# STM32F205 register map
File version: 1.2
CPU: CM3 r1p1, little endian, no MPU, no FPU, 4 interrupt priority bits
Registers are 32-bit, read-write, reset 0x0 unless marked. A register's access mark holds for its fields unless they carry their own. Offsets are from the block's base; [hi:lo] are bit positions; {n}, {i} and the like mark numbered series.

## OTG_FS_PWRCLK — USB on the go full speed
Base 0x50000E00
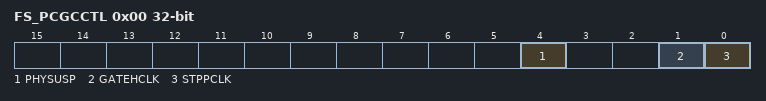
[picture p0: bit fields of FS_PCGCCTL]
0x00 FS_PCGCCTL — OTG_FS power and clock gating control register (OTG_FS_PCGCCTL)
  [4] PHYSUSP — PHY Suspended
  [1] GATEHCLK
  [0] STPPCLK — Stop PHY clock

## OTG_HS_PWRCLK — USB on the go high speed
Base 0x40040E00
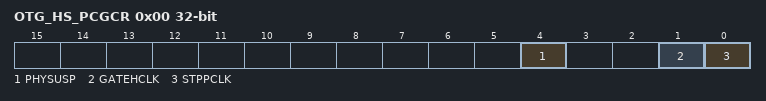
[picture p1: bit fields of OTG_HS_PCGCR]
0x00 OTG_HS_PCGCR — Power and clock gating control register
  [4] PHYSUSP — PHY suspended
  [1] GATEHCLK
  [0] STPPCLK — Stop PHY clock

## PWR — Power control
Base 0x40007000
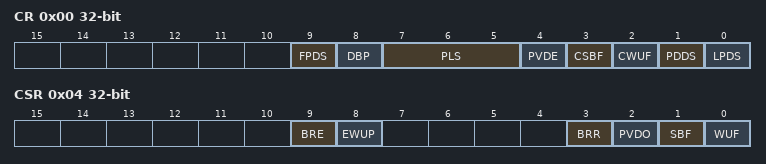
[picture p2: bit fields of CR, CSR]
0x00 CR — power control register
  [9] FPDS — Flash power down in Stop mode
  [8] DBP — Disable backup domain write protection
  [7:5] PLS — PVD level selection
  [4] PVDE — Power voltage detector enable
  [3] CSBF — Clear standby flag
  [2] CWUF — Clear wakeup flag
  [1] PDDS — Power down deepsleep
  [0] LPDS — Low-power deep sleep
0x04 CSR access per field — power control/status register
  [9] BRE rw — Backup regulator enable
  [8] EWUP rw — Enable WKUP pin
  [3] BRR ro — Backup regulator ready
  [2] PVDO ro — PVD output
  [1] SBF ro — Standby flag
  [0] WUF ro — Wakeup flag

## RNG — Random number generator
Base 0x50060800
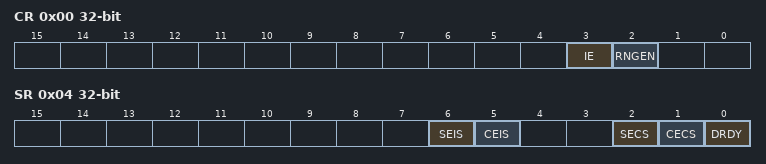
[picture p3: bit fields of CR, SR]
0x00 CR — control register
  [3] IE — Interrupt enable
  [2] RNGEN — Random number generator enable
0x04 SR access per field — status register
  [6] SEIS rw — Seed error interrupt status
  [5] CEIS rw — Clock error interrupt status
  [2] SECS ro — Seed error current status
  [1] CECS ro — Clock error current status
  [0] DRDY ro — Data ready
0x08 DR ro — data register
  [31:0] RNDATA — Random data

## SPI1 — Serial peripheral interface
Base 0x40013000
Same registers: SPI2 0x40003800, SPI3 0x40003C00
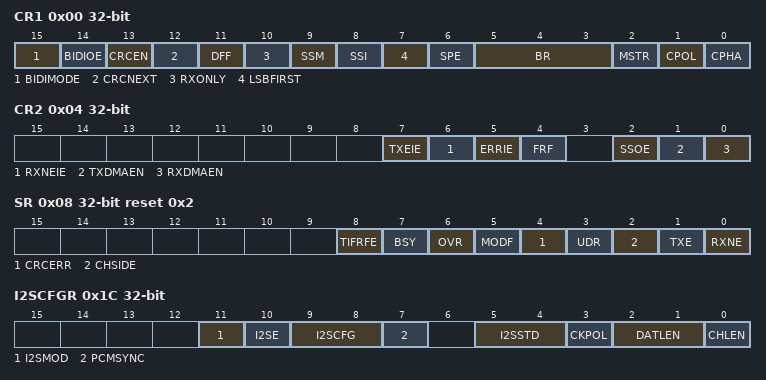
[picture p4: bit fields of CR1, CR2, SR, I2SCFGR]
0x00 CR1 — control register 1
  [15] BIDIMODE — Bidirectional data mode enable
  [14] BIDIOE — Output enable in bidirectional mode
  [13] CRCEN — Hardware CRC calculation enable
  [12] CRCNEXT — CRC transfer next
  [11] DFF — Data frame format
  [10] RXONLY — Receive only
  [9] SSM — Software slave management
  [8] SSI — Internal slave select
  [7] LSBFIRST — Frame format
  [6] SPE — SPI enable
  [5:3] BR — Baud rate control
  [2] MSTR — Master selection
  [1] CPOL — Clock polarity
  [0] CPHA — Clock phase
0x04 CR2 — control register 2
  [7] TXEIE — Tx buffer empty interrupt enable
  [6] RXNEIE — RX buffer not empty interrupt enable
  [5] ERRIE — Error interrupt enable
  [4] FRF — Frame format
  [2] SSOE — SS output enable
  [1] TXDMAEN — Tx buffer DMA enable
  [0] RXDMAEN — Rx buffer DMA enable
0x08 SR access per field reset 0x2 — status register
  [8] TIFRFE ro — TI frame format error
  [7] BSY ro — Busy flag
  [6] OVR ro — Overrun flag
  [5] MODF ro — Mode fault
  [4] CRCERR rw — CRC error flag
  [3] UDR ro — Underrun flag
  [2] CHSIDE ro — Channel side
  [1] TXE ro — Transmit buffer empty
  [0] RXNE ro — Receive buffer not empty
0x0C DR — data register
  [15:0] DR — Data register
0x10 CRCPR reset 0x7 — CRC polynomial register
  [15:0] CRCPOLY
0x14 RXCRCR ro — RX CRC register
  [15:0] RxCRC
0x18 TXCRCR ro — TX CRC register
  [15:0] TxCRC
0x1C I2SCFGR — I2S configuration register
  [11] I2SMOD — I2S mode selection
  [10] I2SE — I2S Enable
  [9:8] I2SCFG — I2S configuration mode
  [7] PCMSYNC — PCM frame synchronization
  [5:4] I2SSTD — I2S standard selection
  [3] CKPOL — Steady state clock polarity
  [2:1] DATLEN — Data length to be transferred
  [0] CHLEN — Channel length (number of bits per audio channel)
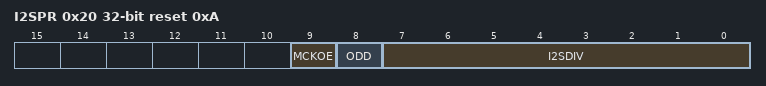
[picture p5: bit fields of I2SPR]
0x20 I2SPR reset 0xA — I2S prescaler register
  [9] MCKOE — Master clock output enable
  [8] ODD — Odd factor for the prescaler
  [7:0] I2SDIV — I2S Linear prescaler

## SYSCFG — System configuration controller
Base 0x40013800
0x00 MEMRM — memory remap register
  [1:0] MEM_MODE
0x04 PMC — peripheral mode configuration register
  [23] MII_RMII_SEL — Ethernet PHY interface selection
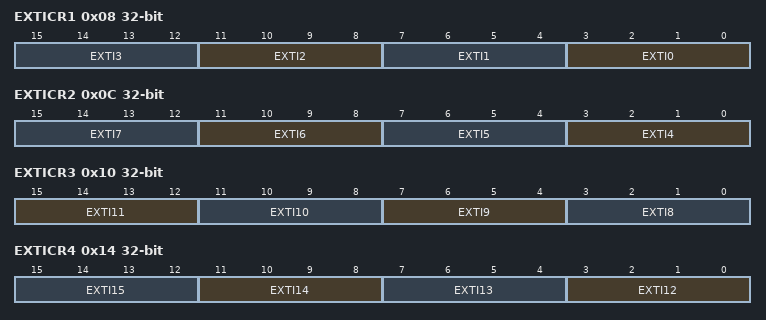
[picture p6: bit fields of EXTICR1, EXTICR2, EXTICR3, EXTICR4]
0x08 EXTICR1 — external interrupt configuration register 1
  [4n+3:4n] EXTI{n} (n=0..3) — EXTI x configuration (x = 0 to 3)
0x0C EXTICR2 — external interrupt configuration register 2
  [4n-13:4n-16] EXTI{n} (n=4..7) — EXTI x configuration (x = 4 to 7)
0x10 EXTICR3 — external interrupt configuration register 3
  [15:12] EXTI11 — EXTI x configuration (x = 8 to 11)
  [11:8] EXTI10
  [7:4] EXTI9 — EXTI x configuration (x = 8 to 11)
  [3:0] EXTI8 — EXTI x configuration (x = 8 to 11)
0x14 EXTICR4 — external interrupt configuration register 4
  [4n-45:4n-48] EXTI{n} (n=12..15) — EXTI x configuration (x = 12 to 15)
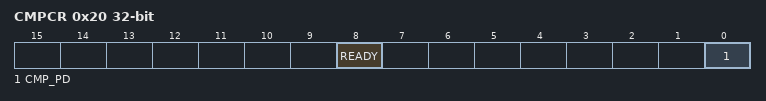
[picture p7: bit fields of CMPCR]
0x20 CMPCR access per field — Compensation cell control register
  [8] READY ro
  [0] CMP_PD rw — Compensation cell power-down
